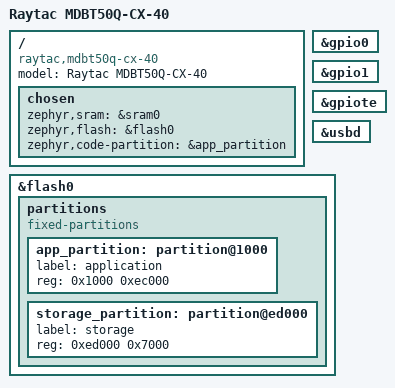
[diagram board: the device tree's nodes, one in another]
/dts-v1/;
#include <nordic/nrf52840_qiaa.dtsi>

/ {
    model = "Raytac MDBT50Q-CX-40";
    compatible = "raytac,mdbt50q-cx-40";
    chosen {
        zephyr,sram = &sram0;
        zephyr,flash = &flash0;
        zephyr,code-partition = &app_partition;
    };
};

&gpio0 { status = "okay"; };
&gpio1 { status = "okay"; };
&gpiote { status = "okay"; };
zephyr_udc0: &usbd { status = "okay"; };

&flash0 {
    partitions {
        compatible = "fixed-partitions";
        #address-cells = <1>;
        #size-cells = <1>;
        // The factory DFU bootloader launches the application after the 4 KiB MBR.
        app_partition: partition@1000 {
            label = "application";
            reg = <0x1000 0xec000>;
        };
        storage_partition: partition@ed000 {
            label = "storage";
            reg = <0xed000 0x7000>;
        };
    };
};
